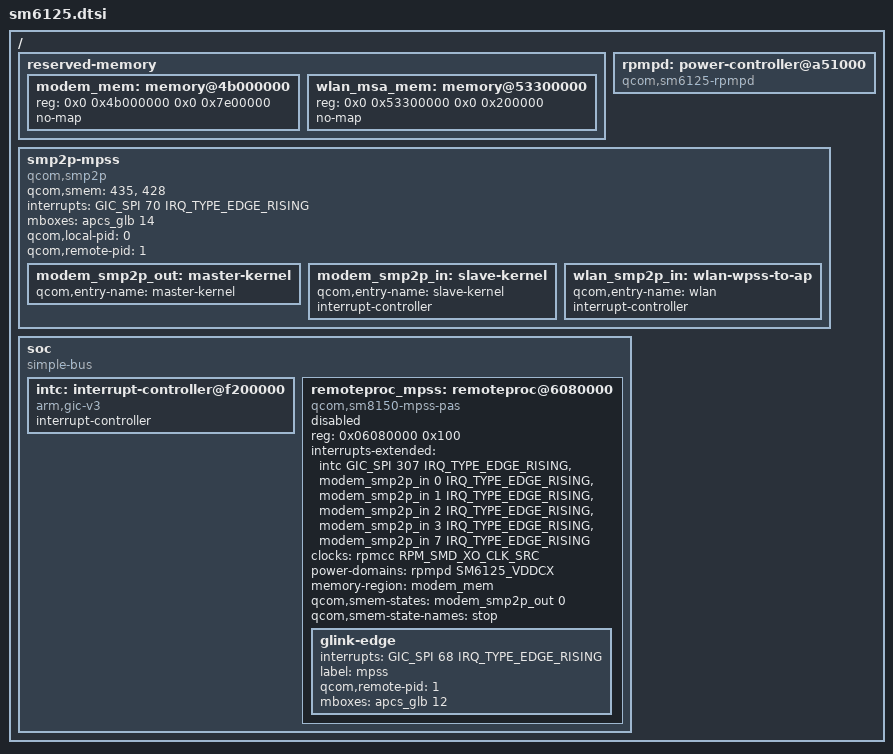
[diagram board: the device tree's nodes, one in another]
// SPDX-License-Identifier: BSD-3-Clause
/*
 * Fixture fuente MPSS v3 (sm6125.dtsi) para el modo --tree del wrapper
 * verify-wcn3990-mpss-v2.sh. Contiene los bloques que el validador extrae:
 * remoteproc_mpss (status disabled en DTSI), smp2p-mpss, modem_mem y
 * wlan_msa_mem. El estado efectivo lo decide el override del board.
 */

/dts-v1/;

/ {
	#address-cells = <2>;
	#size-cells = <2>;

	reserved-memory {
		#address-cells = <2>;
		#size-cells = <2>;
		ranges;

		modem_mem: memory@4b000000 {
			reg = <0x0 0x4b000000 0x0 0x7e00000>;
			no-map;
		};

		wlan_msa_mem: memory@53300000 {
			reg = <0x0 0x53300000 0x0 0x200000>;
			no-map;
		};
	};

	rpmpd: power-controller@a51000 {
		compatible = "qcom,sm6125-rpmpd";
		#power-domain-cells = <1>;
	};

	smp2p-mpss {
		compatible = "qcom,smp2p";
		qcom,smem = <435>, <428>;

		interrupts = <GIC_SPI 70 IRQ_TYPE_EDGE_RISING>;
		mboxes = <&apcs_glb 14>;

		qcom,local-pid = <0>;
		qcom,remote-pid = <1>;

		modem_smp2p_out: master-kernel {
			qcom,entry-name = "master-kernel";
			#qcom,smem-state-cells = <1>;
		};

		modem_smp2p_in: slave-kernel {
			qcom,entry-name = "slave-kernel";
			interrupt-controller;
			#interrupt-cells = <2>;
		};

		wlan_smp2p_in: wlan-wpss-to-ap {
			qcom,entry-name = "wlan";
			interrupt-controller;
			#interrupt-cells = <2>;
		};
	};

	soc {
		#address-cells = <1>;
		#size-cells = <1>;
		ranges = <0x00 0x00 0x00 0xffffffff>;
		compatible = "simple-bus";

		intc: interrupt-controller@f200000 {
			compatible = "arm,gic-v3";
			#interrupt-cells = <3>;
			interrupt-controller;
		};

		remoteproc_mpss: remoteproc@6080000 {
			compatible = "qcom,sm8150-mpss-pas";
			reg = <0x06080000 0x100>;

			interrupts-extended = <&intc GIC_SPI 307 IRQ_TYPE_EDGE_RISING>,
					      <&modem_smp2p_in 0 IRQ_TYPE_EDGE_RISING>,
					      <&modem_smp2p_in 1 IRQ_TYPE_EDGE_RISING>,
					      <&modem_smp2p_in 2 IRQ_TYPE_EDGE_RISING>,
					      <&modem_smp2p_in 3 IRQ_TYPE_EDGE_RISING>,
					      <&modem_smp2p_in 7 IRQ_TYPE_EDGE_RISING>;
			interrupt-names = "wdog", "fatal", "ready",
					  "handover", "stop-ack", "shutdown-ack";

			clocks = <&rpmcc RPM_SMD_XO_CLK_SRC>;
			clock-names = "xo";

			power-domains = <&rpmpd SM6125_VDDCX>;

			memory-region = <&modem_mem>;

			qcom,smem-states = <&modem_smp2p_out 0>;
			qcom,smem-state-names = "stop";

			status = "disabled";

			glink-edge {
				interrupts = <GIC_SPI 68 IRQ_TYPE_EDGE_RISING>;
				label = "mpss";
				qcom,remote-pid = <1>;
				mboxes = <&apcs_glb 12>;
			};
		};
	};
};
